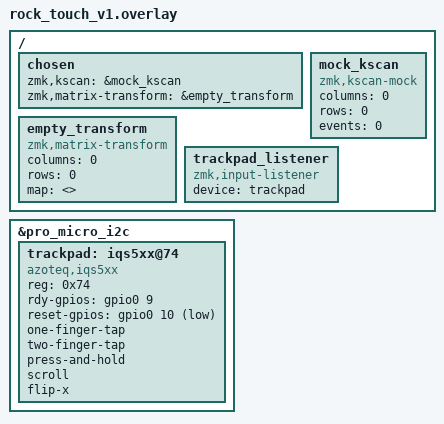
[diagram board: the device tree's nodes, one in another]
// RockTouch V1 — Azoteq IQS5XX trackpad on nice!nano v2.
// I2C (board default via &pro_micro_i2c): SDA P0.17, SCL P0.20.

/ {
    chosen {
        zmk,kscan = &mock_kscan;
        zmk,matrix-transform = &empty_transform;
    };

    mock_kscan: mock_kscan {
        compatible = "zmk,kscan-mock";
        columns = <0>;
        rows = <0>;
        events = <0>;
    };

    empty_transform: empty_transform {
        compatible = "zmk,matrix-transform";
        columns = <0>;
        rows = <0>;
        map = <>;
    };

    trackpad_listener {
        compatible = "zmk,input-listener";
        device = <&trackpad>;
    };
};

&pro_micro_i2c {
    status = "okay";

    trackpad: iqs5xx@74 {
        compatible = "azoteq,iqs5xx";
        reg = <0x74>;
        status = "okay";

        rdy-gpios = <&gpio0 9 GPIO_ACTIVE_HIGH>;   /* P0.09 / D10 */
        reset-gpios = <&gpio0 10 GPIO_ACTIVE_LOW>; /* P0.10 / D16 */

        one-finger-tap;
        two-finger-tap;
        press-and-hold;
        scroll;
        flip-x;
    };
};
